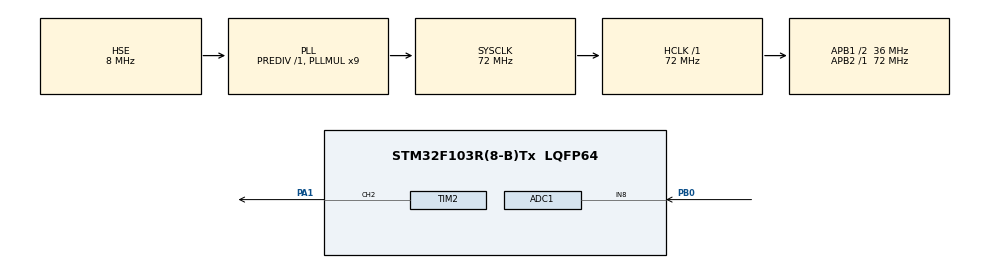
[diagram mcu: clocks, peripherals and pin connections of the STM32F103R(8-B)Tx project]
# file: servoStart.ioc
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ADC1.Channel-0\#ChannelRegularConversion=ADC_CHANNEL_8
ADC1.ContinuousConvMode=ENABLE
ADC1.NbrOfConversionFlag=1
ADC1.Rank-0\#ChannelRegularConversion=1
ADC1.SamplingTime-0\#ChannelRegularConversion=ADC_SAMPLETIME_1CYCLE_5
ADC1.master=1
Mcu.Family=STM32F1
Mcu.Name=STM32F103R(8-B)Tx
Mcu.Package=LQFP64
NVIC.PriorityGroup=NVIC_PRIORITYGROUP_4
NVIC.TIM2_IRQn=true\:0\:0\:false\:false\:true\:true\:true\:true
PA1.Signal=S_TIM2_CH2
PA13.Mode=Trace_Asynchronous_SW
PA13.Signal=SYS_JTMS-SWDIO
PA14.Mode=Trace_Asynchronous_SW
PA14.Signal=SYS_JTCK-SWCLK
PB0.Signal=ADCx_IN8
PB3.Mode=Trace_Asynchronous_SW
PB3.Signal=SYS_JTDO-TRACESWO
PD0-OSC_IN.Mode=HSE-External-Oscillator
PD0-OSC_IN.Signal=RCC_OSC_IN
PD1-OSC_OUT.Mode=HSE-External-Oscillator
PD1-OSC_OUT.Signal=RCC_OSC_OUT
ProjectManager.HeapSize=0x200
ProjectManager.StackSize=0x400
ProjectManager.TargetToolchain=STM32CubeIDE
RCC.ADCPresc=RCC_ADCPCLK2_DIV6
RCC.AHBFreq_Value=72000000
RCC.APB1CLKDivider=RCC_HCLK_DIV2
RCC.APB1Freq_Value=36000000
RCC.APB1TimFreq_Value=72000000
RCC.APB2Freq_Value=72000000
RCC.APB2TimFreq_Value=72000000
RCC.HCLKFreq_Value=72000000
RCC.PLLMUL=RCC_PLL_MUL9
RCC.PLLSourceVirtual=RCC_PLLSOURCE_HSE
RCC.SYSCLKFreq_VALUE=72000000
RCC.SYSCLKSource=RCC_SYSCLKSOURCE_PLLCLK
RCC.USBFreq_Value=72000000
SH.ADCx_IN8.0=ADC1_IN8,IN8
SH.S_TIM2_CH2.0=TIM2_CH2,PWM Generation2 CH2
TIM2.Channel-PWM\ Generation2\ CH2=TIM_CHANNEL_2
TIM2.OCFastMode_PWM-PWM\ Generation2\ CH2=TIM_OCFAST_ENABLE
TIM2.Period=54539
TIM2.Prescaler=3
VP_TIM2_VS_ClockSourceINT.Mode=Internal
board=custom

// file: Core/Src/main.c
/* USER CODE BEGIN Header */
/**
 ******************************************************************************
 * @file           : main.c
 * @brief          : Main program body
 ******************************************************************************
 * @attention
 *
 * Copyright (c) 2024 STMicroelectronics.
 * All rights reserved.
 *
 * This software is licensed under terms that can be found in the LICENSE file
 * in the root directory of this software component.
 * If no LICENSE file comes with this software, it is provided AS-IS.
 *
 ******************************************************************************
 */
/* USER CODE END Header */
#include "main.h"

/* USER CODE BEGIN Includes */
#include <stdio.h>
/* USER CODE END Includes */

ADC_HandleTypeDef hadc1;

TIM_HandleTypeDef htim2;

void SystemClock_Config(void);
static void MX_GPIO_Init(void);
static void MX_TIM2_Init(void);
static void MX_ADC1_Init(void);
/* USER CODE BEGIN PFP */
void servo_deg(uint8_t deg);
/* USER CODE END PFP */

/* USER CODE BEGIN 0 */
uint16_t readValue = 0;
uint16_t ms = 0;
uint16_t angle = 0;

/*-------Конвертор градусов------*/
void servo_deg(uint8_t deg) {
	deg >= 180 ? deg = 180 : deg;
	ms = 9000 + (deg * 200);
	TIM2->CCR2 = ms;
}
/*-------Конвертор градусов------*/
/*-------Конвертор сигнала потенциометра------*/
uint16_t map(uint16_t x, uint16_t in_min, uint16_t in_max, uint16_t out_min,
		uint16_t out_max) {
	return (x - in_min) * (out_max - out_min) / (in_max - in_min) + out_min;
}
/*-------Конвертор сигнала потенциометра------*/
/* USER CODE END 0 */

int main(void) {

	/* MCU Configuration--------------------------------------------------------*/

	/* Reset of all peripherals, Initializes the Flash interface and the Systick. */
	HAL_Init();

	/* Configure the system clock */
	SystemClock_Config();

	/* Initialize all configured peripherals */
	MX_GPIO_Init();
	MX_TIM2_Init();
	MX_ADC1_Init();
	/* USER CODE BEGIN 2 */
	HAL_TIM_PWM_Start_IT(&htim2, TIM_CHANNEL_2);
	HAL_ADC_Start(&hadc1);

	/* USER CODE END 2 */

	/* Infinite loop */
	while (1) {

		/* USER CODE BEGIN 3 */
		HAL_ADC_PollForConversion(&hadc1, 1000);
		readValue = HAL_ADC_GetValue(&hadc1)/100; //делю, так как серво попадает в "мертвую зону"
		angle = map(readValue, 0, 40, 0, 180);
		servo_deg(angle);
	}
	/* USER CODE END 3 */
}

void SystemClock_Config(void) {
	RCC_OscInitTypeDef RCC_OscInitStruct = { 0 };
	RCC_ClkInitTypeDef RCC_ClkInitStruct = { 0 };
	RCC_PeriphCLKInitTypeDef PeriphClkInit = { 0 };

	/** Initializes the RCC Oscillators according to the specified parameters
	 * in the RCC_OscInitTypeDef structure.
	 */
	RCC_OscInitStruct.OscillatorType = RCC_OSCILLATORTYPE_HSE;
	RCC_OscInitStruct.HSEState = RCC_HSE_ON;
	RCC_OscInitStruct.HSEPredivValue = RCC_HSE_PREDIV_DIV1;
	RCC_OscInitStruct.HSIState = RCC_HSI_ON;
	RCC_OscInitStruct.PLL.PLLState = RCC_PLL_ON;
	RCC_OscInitStruct.PLL.PLLSource = RCC_PLLSOURCE_HSE;
	RCC_OscInitStruct.PLL.PLLMUL = RCC_PLL_MUL9;
	if (HAL_RCC_OscConfig(&RCC_OscInitStruct) != HAL_OK) {
		Error_Handler();
	}

	/** Initializes the CPU, AHB and APB buses clocks
	 */
	RCC_ClkInitStruct.ClockType = RCC_CLOCKTYPE_HCLK | RCC_CLOCKTYPE_SYSCLK
			| RCC_CLOCKTYPE_PCLK1 | RCC_CLOCKTYPE_PCLK2;
	RCC_ClkInitStruct.SYSCLKSource = RCC_SYSCLKSOURCE_PLLCLK;
	RCC_ClkInitStruct.AHBCLKDivider = RCC_SYSCLK_DIV1;
	RCC_ClkInitStruct.APB1CLKDivider = RCC_HCLK_DIV2;
	RCC_ClkInitStruct.APB2CLKDivider = RCC_HCLK_DIV1;

	if (HAL_RCC_ClockConfig(&RCC_ClkInitStruct, FLASH_LATENCY_2) != HAL_OK) {
		Error_Handler();
	}
	PeriphClkInit.PeriphClockSelection = RCC_PERIPHCLK_ADC;
	PeriphClkInit.AdcClockSelection = RCC_ADCPCLK2_DIV6;
	if (HAL_RCCEx_PeriphCLKConfig(&PeriphClkInit) != HAL_OK) {
		Error_Handler();
	}
}

static void MX_ADC1_Init(void) {

	ADC_ChannelConfTypeDef sConfig = { 0 };

	/** Common config
	 */
	hadc1.Instance = ADC1;
	hadc1.Init.ScanConvMode = ADC_SCAN_DISABLE;
	hadc1.Init.ContinuousConvMode = ENABLE;
	hadc1.Init.DiscontinuousConvMode = DISABLE;
	hadc1.Init.ExternalTrigConv = ADC_SOFTWARE_START;
	hadc1.Init.DataAlign = ADC_DATAALIGN_RIGHT;
	hadc1.Init.NbrOfConversion = 1;
	if (HAL_ADC_Init(&hadc1) != HAL_OK) {
		Error_Handler();
	}

	/** Configure Regular Channel
	 */
	sConfig.Channel = ADC_CHANNEL_8;
	sConfig.Rank = ADC_REGULAR_RANK_1;
	sConfig.SamplingTime = ADC_SAMPLETIME_1CYCLE_5;
	if (HAL_ADC_ConfigChannel(&hadc1, &sConfig) != HAL_OK) {
		Error_Handler();
	}

}

static void MX_TIM2_Init(void) {

	TIM_ClockConfigTypeDef sClockSourceConfig = { 0 };
	TIM_MasterConfigTypeDef sMasterConfig = { 0 };
	TIM_OC_InitTypeDef sConfigOC = { 0 };

	htim2.Instance = TIM2;
	htim2.Init.Prescaler = 3;
	htim2.Init.CounterMode = TIM_COUNTERMODE_UP;
	htim2.Init.Period = 54539;
	htim2.Init.ClockDivision = TIM_CLOCKDIVISION_DIV1;
	htim2.Init.AutoReloadPreload = TIM_AUTORELOAD_PRELOAD_DISABLE;
	if (HAL_TIM_Base_Init(&htim2) != HAL_OK) {
		Error_Handler();
	}
	sClockSourceConfig.ClockSource = TIM_CLOCKSOURCE_INTERNAL;
	if (HAL_TIM_ConfigClockSource(&htim2, &sClockSourceConfig) != HAL_OK) {
		Error_Handler();
	}
	if (HAL_TIM_PWM_Init(&htim2) != HAL_OK) {
		Error_Handler();
	}
	sMasterConfig.MasterOutputTrigger = TIM_TRGO_RESET;
	sMasterConfig.MasterSlaveMode = TIM_MASTERSLAVEMODE_DISABLE;
	if (HAL_TIMEx_MasterConfigSynchronization(&htim2, &sMasterConfig)
			!= HAL_OK) {
		Error_Handler();
	}
	sConfigOC.OCMode = TIM_OCMODE_PWM1;
	sConfigOC.Pulse = 0;
	sConfigOC.OCPolarity = TIM_OCPOLARITY_HIGH;
	sConfigOC.OCFastMode = TIM_OCFAST_ENABLE;
	if (HAL_TIM_PWM_ConfigChannel(&htim2, &sConfigOC, TIM_CHANNEL_2)
			!= HAL_OK) {
		Error_Handler();
	}
	HAL_TIM_MspPostInit(&htim2);

}

static void MX_GPIO_Init(void) {

	/* GPIO Ports Clock Enable */
	__HAL_RCC_GPIOD_CLK_ENABLE();
	__HAL_RCC_GPIOA_CLK_ENABLE();
	__HAL_RCC_GPIOB_CLK_ENABLE();

}

void Error_Handler(void) {
	__disable_irq();
	while (1) {
	}
}
